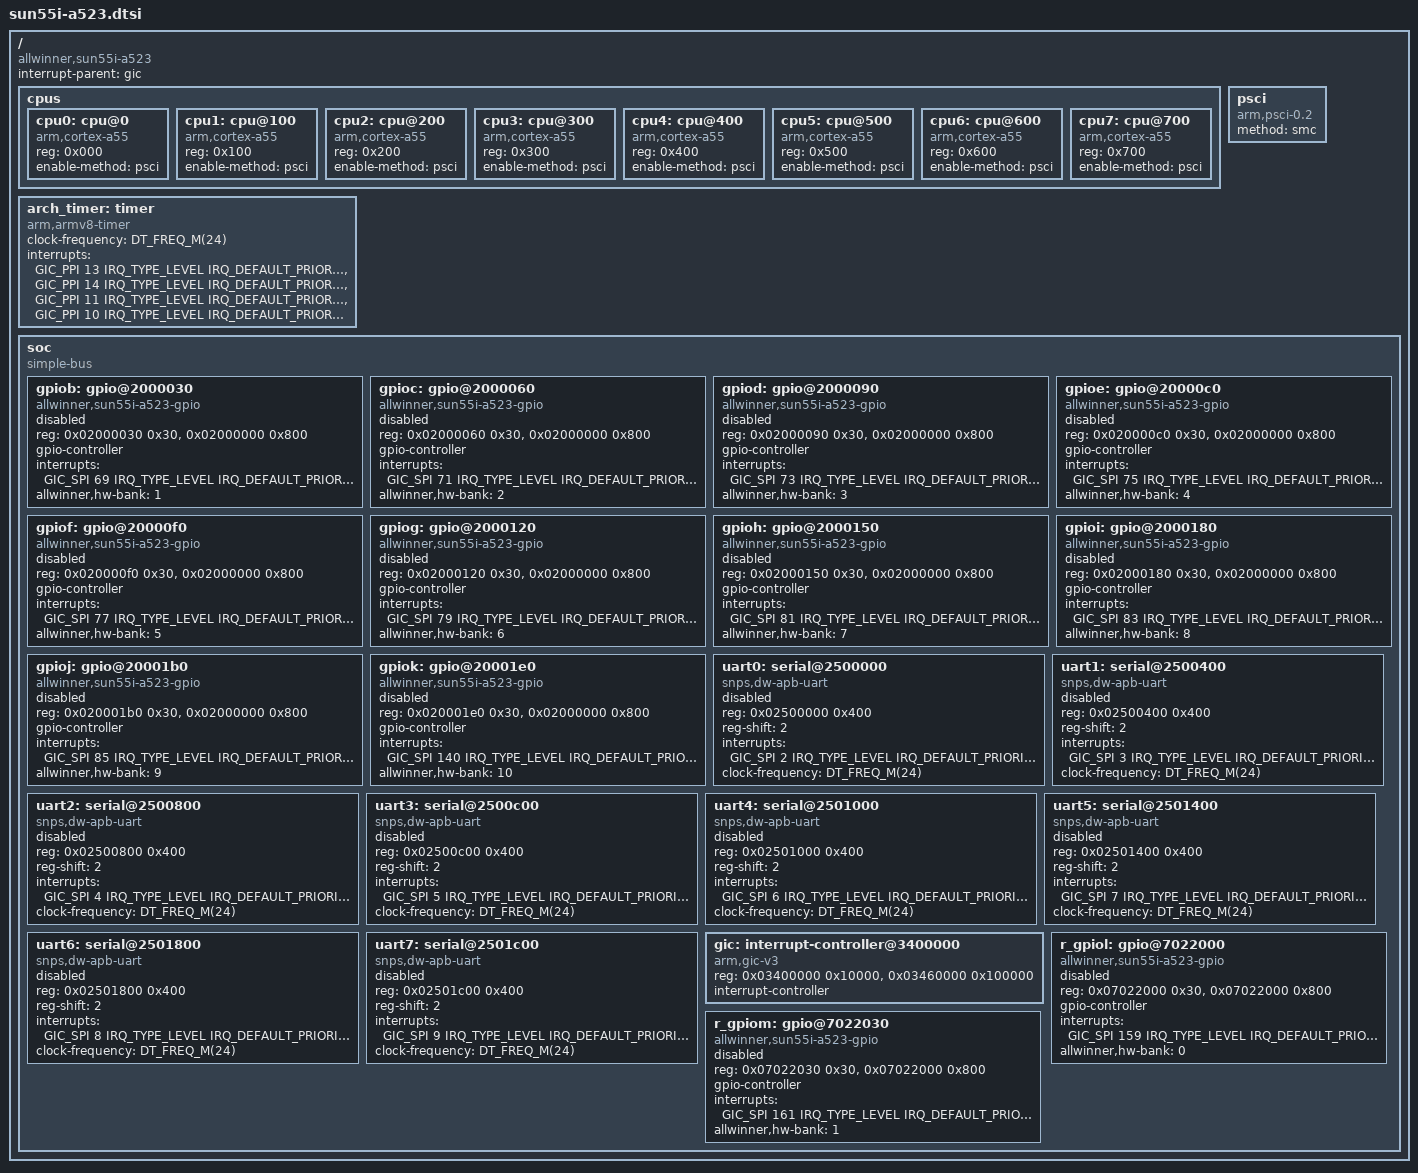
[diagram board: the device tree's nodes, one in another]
/*
 * Copyright The Zephyr Project Contributors
 * SPDX-License-Identifier: Apache-2.0
 *
 * Allwinner A523/A527/T527: two clusters of four Cortex-A55 behind a DSU,
 * GIC-600. Clocks and pin muxing are set up by U-Boot SPL; the cores are
 * started through PSCI (TF-A PLAT=sun55i_a523).
 */

#include <mem.h>
#include <freq.h>

#include <arm64/armv8-a.dtsi>
#include <zephyr/dt-bindings/interrupt-controller/arm-gic.h>

/ {
	compatible = "allwinner,sun55i-a523";
	#address-cells = <1>;
	#size-cells = <1>;
	interrupt-parent = <&gic>;

	cpus {
		#address-cells = <1>;
		#size-cells = <0>;

		cpu0: cpu@0 {
			compatible = "arm,cortex-a55";
			device_type = "cpu";
			reg = <0x000>;
			enable-method = "psci";
		};

		cpu1: cpu@100 {
			compatible = "arm,cortex-a55";
			device_type = "cpu";
			reg = <0x100>;
			enable-method = "psci";
		};

		cpu2: cpu@200 {
			compatible = "arm,cortex-a55";
			device_type = "cpu";
			reg = <0x200>;
			enable-method = "psci";
		};

		cpu3: cpu@300 {
			compatible = "arm,cortex-a55";
			device_type = "cpu";
			reg = <0x300>;
			enable-method = "psci";
		};

		cpu4: cpu@400 {
			compatible = "arm,cortex-a55";
			device_type = "cpu";
			reg = <0x400>;
			enable-method = "psci";
		};

		cpu5: cpu@500 {
			compatible = "arm,cortex-a55";
			device_type = "cpu";
			reg = <0x500>;
			enable-method = "psci";
		};

		cpu6: cpu@600 {
			compatible = "arm,cortex-a55";
			device_type = "cpu";
			reg = <0x600>;
			enable-method = "psci";
		};

		cpu7: cpu@700 {
			compatible = "arm,cortex-a55";
			device_type = "cpu";
			reg = <0x700>;
			enable-method = "psci";
		};
	};

	psci {
		compatible = "arm,psci-0.2";
		method = "smc";
	};

	arch_timer: timer {
		compatible = "arm,armv8-timer";
		clock-frequency = <DT_FREQ_M(24)>;
		interrupts = <GIC_PPI 13 IRQ_TYPE_LEVEL IRQ_DEFAULT_PRIORITY>,
			     <GIC_PPI 14 IRQ_TYPE_LEVEL IRQ_DEFAULT_PRIORITY>,
			     <GIC_PPI 11 IRQ_TYPE_LEVEL IRQ_DEFAULT_PRIORITY>,
			     <GIC_PPI 10 IRQ_TYPE_LEVEL IRQ_DEFAULT_PRIORITY>;
	};

	soc {
		#address-cells = <1>;
		#size-cells = <1>;
		compatible = "simple-bus";
		ranges;

		/*
		 * GPIO banks: 0x30 bytes per bank, the interrupt registers at
		 * 0x200 + bank * 0x20 of the pin controller. No port A.
		 */
		gpiob: gpio@2000030 {
			compatible = "allwinner,sun55i-a523-gpio", "allwinner,sunxi-gpio";
			reg = <0x02000030 0x30>, <0x02000000 0x800>;
			reg-names = "reg_base", "pio_base";
			gpio-controller;
			#gpio-cells = <2>;
			interrupts = <GIC_SPI 69 IRQ_TYPE_LEVEL IRQ_DEFAULT_PRIORITY>;
			allwinner,hw-bank = <1>;
			status = "disabled";
		};

		gpioc: gpio@2000060 {
			compatible = "allwinner,sun55i-a523-gpio", "allwinner,sunxi-gpio";
			reg = <0x02000060 0x30>, <0x02000000 0x800>;
			reg-names = "reg_base", "pio_base";
			gpio-controller;
			#gpio-cells = <2>;
			interrupts = <GIC_SPI 71 IRQ_TYPE_LEVEL IRQ_DEFAULT_PRIORITY>;
			allwinner,hw-bank = <2>;
			status = "disabled";
		};

		gpiod: gpio@2000090 {
			compatible = "allwinner,sun55i-a523-gpio", "allwinner,sunxi-gpio";
			reg = <0x02000090 0x30>, <0x02000000 0x800>;
			reg-names = "reg_base", "pio_base";
			gpio-controller;
			#gpio-cells = <2>;
			interrupts = <GIC_SPI 73 IRQ_TYPE_LEVEL IRQ_DEFAULT_PRIORITY>;
			allwinner,hw-bank = <3>;
			status = "disabled";
		};

		gpioe: gpio@20000c0 {
			compatible = "allwinner,sun55i-a523-gpio", "allwinner,sunxi-gpio";
			reg = <0x020000c0 0x30>, <0x02000000 0x800>;
			reg-names = "reg_base", "pio_base";
			gpio-controller;
			#gpio-cells = <2>;
			interrupts = <GIC_SPI 75 IRQ_TYPE_LEVEL IRQ_DEFAULT_PRIORITY>;
			allwinner,hw-bank = <4>;
			status = "disabled";
		};

		gpiof: gpio@20000f0 {
			compatible = "allwinner,sun55i-a523-gpio", "allwinner,sunxi-gpio";
			reg = <0x020000f0 0x30>, <0x02000000 0x800>;
			reg-names = "reg_base", "pio_base";
			gpio-controller;
			#gpio-cells = <2>;
			interrupts = <GIC_SPI 77 IRQ_TYPE_LEVEL IRQ_DEFAULT_PRIORITY>;
			allwinner,hw-bank = <5>;
			status = "disabled";
		};

		gpiog: gpio@2000120 {
			compatible = "allwinner,sun55i-a523-gpio", "allwinner,sunxi-gpio";
			reg = <0x02000120 0x30>, <0x02000000 0x800>;
			reg-names = "reg_base", "pio_base";
			gpio-controller;
			#gpio-cells = <2>;
			interrupts = <GIC_SPI 79 IRQ_TYPE_LEVEL IRQ_DEFAULT_PRIORITY>;
			allwinner,hw-bank = <6>;
			status = "disabled";
		};

		gpioh: gpio@2000150 {
			compatible = "allwinner,sun55i-a523-gpio", "allwinner,sunxi-gpio";
			reg = <0x02000150 0x30>, <0x02000000 0x800>;
			reg-names = "reg_base", "pio_base";
			gpio-controller;
			#gpio-cells = <2>;
			interrupts = <GIC_SPI 81 IRQ_TYPE_LEVEL IRQ_DEFAULT_PRIORITY>;
			allwinner,hw-bank = <7>;
			status = "disabled";
		};

		gpioi: gpio@2000180 {
			compatible = "allwinner,sun55i-a523-gpio", "allwinner,sunxi-gpio";
			reg = <0x02000180 0x30>, <0x02000000 0x800>;
			reg-names = "reg_base", "pio_base";
			gpio-controller;
			#gpio-cells = <2>;
			interrupts = <GIC_SPI 83 IRQ_TYPE_LEVEL IRQ_DEFAULT_PRIORITY>;
			allwinner,hw-bank = <8>;
			status = "disabled";
		};

		gpioj: gpio@20001b0 {
			compatible = "allwinner,sun55i-a523-gpio", "allwinner,sunxi-gpio";
			reg = <0x020001b0 0x30>, <0x02000000 0x800>;
			reg-names = "reg_base", "pio_base";
			gpio-controller;
			#gpio-cells = <2>;
			interrupts = <GIC_SPI 85 IRQ_TYPE_LEVEL IRQ_DEFAULT_PRIORITY>;
			allwinner,hw-bank = <9>;
			status = "disabled";
		};

		gpiok: gpio@20001e0 {
			compatible = "allwinner,sun55i-a523-gpio", "allwinner,sunxi-gpio";
			reg = <0x020001e0 0x30>, <0x02000000 0x800>;
			reg-names = "reg_base", "pio_base";
			gpio-controller;
			#gpio-cells = <2>;
			interrupts = <GIC_SPI 140 IRQ_TYPE_LEVEL IRQ_DEFAULT_PRIORITY>;
			allwinner,hw-bank = <10>;
			status = "disabled";
		};

		uart0: serial@2500000 {
			compatible = "snps,dw-apb-uart", "ns16550";
			reg = <0x02500000 0x400>;
			reg-shift = <2>;
			interrupts = <GIC_SPI 2 IRQ_TYPE_LEVEL IRQ_DEFAULT_PRIORITY>;
			clock-frequency = <DT_FREQ_M(24)>;
			status = "disabled";
		};

		uart1: serial@2500400 {
			compatible = "snps,dw-apb-uart", "ns16550";
			reg = <0x02500400 0x400>;
			reg-shift = <2>;
			interrupts = <GIC_SPI 3 IRQ_TYPE_LEVEL IRQ_DEFAULT_PRIORITY>;
			clock-frequency = <DT_FREQ_M(24)>;
			status = "disabled";
		};

		uart2: serial@2500800 {
			compatible = "snps,dw-apb-uart", "ns16550";
			reg = <0x02500800 0x400>;
			reg-shift = <2>;
			interrupts = <GIC_SPI 4 IRQ_TYPE_LEVEL IRQ_DEFAULT_PRIORITY>;
			clock-frequency = <DT_FREQ_M(24)>;
			status = "disabled";
		};

		uart3: serial@2500c00 {
			compatible = "snps,dw-apb-uart", "ns16550";
			reg = <0x02500c00 0x400>;
			reg-shift = <2>;
			interrupts = <GIC_SPI 5 IRQ_TYPE_LEVEL IRQ_DEFAULT_PRIORITY>;
			clock-frequency = <DT_FREQ_M(24)>;
			status = "disabled";
		};

		uart4: serial@2501000 {
			compatible = "snps,dw-apb-uart", "ns16550";
			reg = <0x02501000 0x400>;
			reg-shift = <2>;
			interrupts = <GIC_SPI 6 IRQ_TYPE_LEVEL IRQ_DEFAULT_PRIORITY>;
			clock-frequency = <DT_FREQ_M(24)>;
			status = "disabled";
		};

		uart5: serial@2501400 {
			compatible = "snps,dw-apb-uart", "ns16550";
			reg = <0x02501400 0x400>;
			reg-shift = <2>;
			interrupts = <GIC_SPI 7 IRQ_TYPE_LEVEL IRQ_DEFAULT_PRIORITY>;
			clock-frequency = <DT_FREQ_M(24)>;
			status = "disabled";
		};

		uart6: serial@2501800 {
			compatible = "snps,dw-apb-uart", "ns16550";
			reg = <0x02501800 0x400>;
			reg-shift = <2>;
			interrupts = <GIC_SPI 8 IRQ_TYPE_LEVEL IRQ_DEFAULT_PRIORITY>;
			clock-frequency = <DT_FREQ_M(24)>;
			status = "disabled";
		};

		uart7: serial@2501c00 {
			compatible = "snps,dw-apb-uart", "ns16550";
			reg = <0x02501c00 0x400>;
			reg-shift = <2>;
			interrupts = <GIC_SPI 9 IRQ_TYPE_LEVEL IRQ_DEFAULT_PRIORITY>;
			clock-frequency = <DT_FREQ_M(24)>;
			status = "disabled";
		};

		gic: interrupt-controller@3400000 {
			compatible = "arm,gic-v3", "arm,gic";
			reg = <0x03400000 0x10000>, /* GICD */
			      <0x03460000 0x100000>; /* GICR: 8 x 128 KiB */
			#address-cells = <1>;
			#interrupt-cells = <4>;
			interrupt-controller;
			status = "okay";
		};

		r_gpiol: gpio@7022000 {
			compatible = "allwinner,sun55i-a523-gpio", "allwinner,sunxi-gpio";
			reg = <0x07022000 0x30>, <0x07022000 0x800>;
			reg-names = "reg_base", "pio_base";
			gpio-controller;
			#gpio-cells = <2>;
			interrupts = <GIC_SPI 159 IRQ_TYPE_LEVEL IRQ_DEFAULT_PRIORITY>;
			allwinner,hw-bank = <0>;
			status = "disabled";
		};

		r_gpiom: gpio@7022030 {
			compatible = "allwinner,sun55i-a523-gpio", "allwinner,sunxi-gpio";
			reg = <0x07022030 0x30>, <0x07022000 0x800>;
			reg-names = "reg_base", "pio_base";
			gpio-controller;
			#gpio-cells = <2>;
			interrupts = <GIC_SPI 161 IRQ_TYPE_LEVEL IRQ_DEFAULT_PRIORITY>;
			allwinner,hw-bank = <1>;
			status = "disabled";
		};
	};
};
